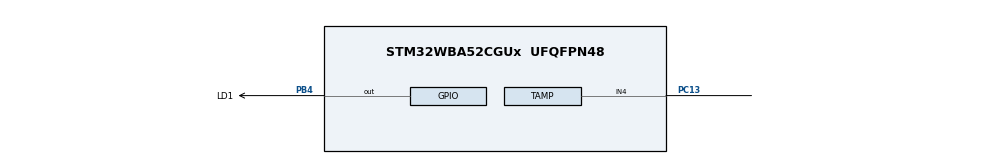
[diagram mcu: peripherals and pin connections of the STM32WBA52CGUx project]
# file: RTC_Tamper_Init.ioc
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CORTEX_M33_NS.userName=CORTEX_M33
Mcu.Family=STM32WBA
Mcu.Name=STM32WBA52CGUx
Mcu.Package=UFQFPN48
NVIC.PriorityGroup=NVIC_PRIORITYGROUP_4
OSC_IN.Mode=HSE-External-Oscillator
OSC_IN.Signal=RCC_OSC_IN
OSC_OUT.Mode=HSE-External-Oscillator
OSC_OUT.Signal=RCC_OSC_OUT
PB4\ (NJTRST).GPIO_Label=LD1
PB4\ (NJTRST).PinState=GPIO_PIN_SET
PB4\ (NJTRST).Signal=GPIO_Output
PC13.Mode=Tamper_4_enabled0
PC13.Signal=TAMP_IN4
ProjectManager.HeapSize=0x200
ProjectManager.StackSize=0x400
ProjectManager.TargetToolchain=EWARM V9.20
RCC.ADCFreq_Value=100000000
RCC.AHB5CLKDivider=DIV4
RCC.AHBFreq_Value=100000000
RCC.APB1Freq_Value=100000000
RCC.APB1TimFreq_Value=100000000
RCC.APB2Freq_Value=100000000
RCC.APB2TimFreq_Value=100000000
RCC.CortexFreq_Value=12500000
RCC.HCLKFreq_Value=100000000
RCC.HSE_VALUE=32000000
RCC.HSI_VALUE=16000000
RCC.LSE_VALUE=32768
RCC.PLLM=4
RCC.PLLN=25
RCC.PLLSourceVirtual=RCC_PLLSOURCE_HSE
RCC.SYSCLKFreq_VALUE=100000000
RCC.SYSCLKSourceVirtual=RCC_SYSCLKSOURCE_PLLCLK
RCC.VCOOutputFreq_Value=200000000
TAMP.Filter=RTC_TAMPERFILTER_8SAMPLE
TAMP.NoErase_4=RTC_TAMPER_ERASE_BACKUP_DISABLE
TAMP.SamplingFrequency=RTC_TAMPERSAMPLINGFREQ_RTCCLK_DIV256
VP_ICACHE_VS_ICACHE.Mode=DirectMappedCache
VP_PWR_VS_SECSignals.Mode=Security/Privilege
VP_RTC_VS_RTC_Activate.Mode=RTC_Enabled
board=custom

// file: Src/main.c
/* USER CODE BEGIN Header */
/**
  ******************************************************************************
  * @file    Examples_LL/RTC/RTC_Tamper_Init/Src/main.c
  * @author  MCD Application Team
  * @brief   This sample code shows how to use STM32WBAxx RTC LL API
  *          to write/read data to/from RTC Backup data registers and demonstrates
  *          the Tamper detection feature.
  ******************************************************************************
  * @attention
  *
  * Copyright (c) 2022 STMicroelectronics.
  * All rights reserved.
  *
  * This software is licensed under terms that can be found in the LICENSE file
  * in the root directory of this software component.
  * If no LICENSE file comes with this software, it is provided AS-IS.
  *
  ******************************************************************************
  */
/* USER CODE END Header */
#include "main.h"

/* USER CODE BEGIN PD */

#define BACKUP_COUNT 32
/* USER CODE END PD */

/* USER CODE BEGIN PV */

__IO FlagStatus TamperStatus = RESET;

/* Backup registers table */
uint32_t aBKPDataReg[BACKUP_COUNT] =
{
  LL_RTC_BKP_DR0,  LL_RTC_BKP_DR1,  LL_RTC_BKP_DR2,
  LL_RTC_BKP_DR3,  LL_RTC_BKP_DR4,  LL_RTC_BKP_DR5,
  LL_RTC_BKP_DR6,  LL_RTC_BKP_DR7,  LL_RTC_BKP_DR8,
  LL_RTC_BKP_DR9,  LL_RTC_BKP_DR10, LL_RTC_BKP_DR11,
  LL_RTC_BKP_DR12, LL_RTC_BKP_DR13, LL_RTC_BKP_DR14,
  LL_RTC_BKP_DR15, LL_RTC_BKP_DR16, LL_RTC_BKP_DR17,
  LL_RTC_BKP_DR18, LL_RTC_BKP_DR19, LL_RTC_BKP_DR20,
  LL_RTC_BKP_DR21, LL_RTC_BKP_DR22, LL_RTC_BKP_DR23,
  LL_RTC_BKP_DR24, LL_RTC_BKP_DR25, LL_RTC_BKP_DR26,
  LL_RTC_BKP_DR27, LL_RTC_BKP_DR28, LL_RTC_BKP_DR29,
  LL_RTC_BKP_DR30, LL_RTC_BKP_DR31
};

/* USER CODE END PV */

void SystemClock_Config(void);
static void MX_GPIO_Init(void);
static void MX_RTC_Init(void);
static void MX_TAMP_RTC_Init(void);
static void MX_ICACHE_Init(void);
/* USER CODE BEGIN PFP */
void     LED_On(void);
void     LED_Blinking(uint32_t Period);
/* USER CODE END PFP */

int main(void)
{
  /* USER CODE BEGIN 1 */

  register uint32_t index = 0;

  /* USER CODE END 1 */

  /* MCU Configuration--------------------------------------------------------*/

  /* Reset of all peripherals, Initializes the Flash interface and the Systick. */

  /* System interrupt init*/
  NVIC_SetPriorityGrouping(NVIC_PRIORITYGROUP_4);

  /* SysTick_IRQn interrupt configuration */
  NVIC_SetPriority(SysTick_IRQn, NVIC_EncodePriority(NVIC_GetPriorityGrouping(),15, 0));

  /* Enable PWR clock interface */

  LL_AHB4_GRP1_EnableClock(LL_AHB4_GRP1_PERIPH_PWR);

  /* USER CODE BEGIN Init */
  /* Enables access to the backup domain */
  LL_PWR_EnableBkUpAccess();

  /* USER CODE END Init */

  /* Configure the system clock */
  SystemClock_Config();

  /* Initialize all configured peripherals */
  MX_GPIO_Init();
  MX_RTC_Init();
  MX_TAMP_RTC_Init();
  MX_ICACHE_Init();
  /* USER CODE BEGIN 2 */
  LL_RTC_ClearFlag_TAMP4(RTC);
  /* Write Data on the Back Up registers  */
  for (index = 0; index < BACKUP_COUNT; index++)
  {
    LL_RTC_BKP_SetRegister(RTC, aBKPDataReg[index], 0xDF59 + (index * 0x5A));
  }

  /* Check Data is stored on the Back Up registers */
  for (index = 0; index < BACKUP_COUNT; index++)
  {
    if (LL_RTC_BKP_GetRegister(RTC, aBKPDataReg[index]) != (0xDF59 + (index * 0x5A)))
    {
      LED_Blinking(LED_BLINK_ERROR);
    }
  }

  /* Wait for Tamper detection */
  while (TamperStatus != SET)
  {
    LL_GPIO_TogglePin(LD1_GPIO_Port, LD1_Pin);
    LL_mDelay(LED_BLINK_FAST);
  }

  /* LD1 On: Tamper button pressed */
  LED_On();

  /* USER CODE END 2 */

  /* Infinite loop */
  while (1)
  {

  }
}

void SystemClock_Config(void)
{
  LL_FLASH_SetLatency(LL_FLASH_LATENCY_3);
  while(LL_FLASH_GetLatency()!= LL_FLASH_LATENCY_3)
  {
  }

  LL_PWR_SetRegulVoltageScaling(LL_PWR_REGU_VOLTAGE_SCALE1);
  LL_RCC_HSE_Enable();

   /* Wait till HSE is ready */
  while(LL_RCC_HSE_IsReady() != 1)
  {
  }

  LL_RCC_LSI1_SetPrescaler(LL_RCC_LSI_DIV_1);
  LL_RCC_LSI1_Enable();

   /* Wait till LSI1 is ready */
  while(LL_RCC_LSI1_IsReady() != 1)
  {
  }

  LL_PWR_EnableBkUpAccess();
  LL_RCC_PLL1_ConfigDomain_SYS(LL_RCC_PLL1SOURCE_HSE, 4, 25, 2);
  LL_RCC_PLL1_EnableDomain_PLL1R();
  LL_RCC_PLL1_SetVCOInputRange(LL_RCC_PLLINPUTRANGE_8_16);
  LL_RCC_PLL1_Enable();

   /* Wait till PLL is ready */
  while(LL_RCC_PLL1_IsReady() != 1)
  {
  }

  LL_RCC_SetSysClkSource(LL_RCC_SYS_CLKSOURCE_PLL1R);

   /* Wait till System clock is ready */
  while(LL_RCC_GetSysClkSource() != LL_RCC_SYS_CLKSOURCE_STATUS_PLL1R)
  {
  }

  LL_RCC_SetAHBPrescaler(LL_RCC_SYSCLK_DIV_1);
  LL_RCC_SetAHB5Prescaler(LL_RCC_AHB5_DIV_4);
  LL_RCC_SetAPB1Prescaler(LL_RCC_APB1_DIV_1);
  LL_RCC_SetAPB2Prescaler(LL_RCC_APB2_DIV_1);
  LL_RCC_SetAPB7Prescaler(LL_RCC_APB7_DIV_1);

  LL_Init1msTick(100000000);

  LL_SetSystemCoreClock(100000000);
}

static void MX_ICACHE_Init(void)
{

  /** Enable instruction cache in 1-way (direct mapped cache)
  */
  LL_ICACHE_SetMode(LL_ICACHE_1WAY);
  LL_ICACHE_Enable();

}

static void MX_RTC_Init(void)
{

  LL_RTC_InitTypeDef RTC_InitStruct = {0};

  if(LL_RCC_GetRTCClockSource() != LL_RCC_RTC_CLKSOURCE_LSI)
  {
    LL_RCC_ForceBackupDomainReset();
    LL_RCC_ReleaseBackupDomainReset();
    LL_RCC_SetRTCClockSource(LL_RCC_RTC_CLKSOURCE_LSI);
  }

  /* Peripheral clock enable */
  LL_APB7_GRP1_EnableClock(LL_APB7_GRP1_PERIPH_RTCAPB);

  /* USER CODE BEGIN RTC_Init 1 */

  /* Enables the PWR Clock and Enables access to the backup domain */
  LL_PWR_EnableBkUpAccess();
  /* USER CODE END RTC_Init 1 */
  RTC_InitStruct.HourFormat = LL_RTC_HOURFORMAT_24HOUR;
  RTC_InitStruct.AsynchPrescaler = 127;
  RTC_InitStruct.SynchPrescaler = 255;
  LL_RTC_Init(RTC, &RTC_InitStruct);
  LL_RTC_SetBackupRegisterPrivilege(RTC, LL_RTC_PRIVILEGE_BKUP_ZONE_NONE);
  LL_RTC_SetBackupRegProtection(RTC, LL_RTC_BKP_DR0, LL_RTC_BKP_DR0);
  LL_RTC_SetRtcPrivilege(RTC, LL_RTC_PRIVILEGE_FULL_NO);
  /* USER CODE BEGIN RTC_Init 2 */
  /* Enable IT TAMPER */
  LL_RTC_EnableIT_TAMP4(RTC);

  /* Configure the NVIC for RTC Tamper */
  NVIC_SetPriority(TAMP_IRQn, 0x0F);
  NVIC_EnableIRQ(TAMP_IRQn);

  /* RTC Tamper Interrupt Configuration: EXTI configuration */
  LL_EXTI_EnableIT_0_31(LL_EXTI_LINE_13);
  LL_EXTI_EnableRisingTrig_0_31(LL_EXTI_LINE_13);

  /* Clear the Tamper interrupt pending bit */
  LL_RTC_ClearFlag_TAMP4(RTC);
  /* USER CODE END RTC_Init 2 */

}

static void MX_TAMP_RTC_Init(void)
{

  /* Peripheral clock enable */

  LL_RTC_SetTampPrivilege(RTC, LL_TAMP_PRIVILEGE_FULL_YES);
  LL_RTC_IncrementMonotonicCounter(RTC);
  LL_RTC_TAMPER_SetFilterCount(RTC, LL_RTC_TAMPER_FILTER_8SAMPLE);
  LL_RTC_TAMPER_SetPrecharge(RTC, LL_RTC_TAMPER_DURATION_1RTCCLK);
  LL_RTC_TAMPER_SetSamplingFreq(RTC, LL_RTC_TAMPER_SAMPLFREQDIV_256);
  LL_RTC_TAMPER_EnablePullUp(RTC);

  /** Enable the RTC Tamper 4
  */
  LL_RTC_TAMPER_Enable(RTC, LL_RTC_TAMPER_4);
  LL_RTC_TAMPER_ATAMP_DisableActiveMode(LL_RTC_TAMPER_ATAMP_TAMP4AM);
  LL_RTC_TAMPER_DisableEraseBKP(RTC, LL_RTC_TAMPER_NOERASE_TAMPER4);
  LL_RTC_TS_EnableOnTamper(RTC);

}

static void MX_GPIO_Init(void)
{
  LL_GPIO_InitTypeDef GPIO_InitStruct = {0};

  /* GPIO Ports Clock Enable */
  LL_AHB2_GRP1_EnableClock(LL_AHB2_GRP1_PERIPH_GPIOC);
  LL_AHB2_GRP1_EnableClock(LL_AHB2_GRP1_PERIPH_GPIOB);

  /**/
  LL_GPIO_SetOutputPin(LD1_GPIO_Port, LD1_Pin);

  /**/
  GPIO_InitStruct.Pin = LD1_Pin;
  GPIO_InitStruct.Mode = LL_GPIO_MODE_OUTPUT;
  GPIO_InitStruct.Speed = LL_GPIO_SPEED_FREQ_LOW;
  GPIO_InitStruct.OutputType = LL_GPIO_OUTPUT_PUSHPULL;
  GPIO_InitStruct.Pull = LL_GPIO_PULL_NO;
  LL_GPIO_Init(LD1_GPIO_Port, &GPIO_InitStruct);

}

/* USER CODE BEGIN 4 */

/**
  * @brief  Turn-on LD1.
  * @param  None
  * @retval None
  */
void LED_On(void)
{
  /* Turn LD1 on */
  LL_GPIO_ResetOutputPin(LD1_GPIO_Port, LD1_Pin);
}

/**
  * @brief  Set LD1 to Blinking mode for an infinite loop (toggle period based on value provided as input parameter).
  * @param  Period : Period of time (in ms) between each toggling of LED
  *   This parameter can be user defined values. Pre-defined values used in that example are :
  *     @arg LED_BLINK_FAST : Fast Blinking
  *     @arg LED_BLINK_SLOW : Slow Blinking
  *     @arg LED_BLINK_ERROR : Error specific Blinking
  * @retval None
  */
void LED_Blinking(uint32_t Period)
{
  /* Toggle IO in an infinite loop */
  while (1)
  {
    LL_GPIO_TogglePin(LD1_GPIO_Port, LD1_Pin);
    LL_mDelay(Period);
  }
}

/******************************************************************************/
/*   USER IRQ HANDLER TREATMENT                                               */
/******************************************************************************/
/**
  * @brief  Tamper event callback function
  * @param  None
  * @retval None
  */
void Tamper_Callback(void)
{
  register uint32_t index = 0;

  /* Deactivate the tamper */
  LL_RTC_TAMPER_Disable(RTC, LL_RTC_TAMPER_4);

  /* Check Data is cleared on the Back Up registers */
  for (index = 0; index < BACKUP_COUNT; index++)
  {
    if (LL_RTC_BKP_GetRegister(RTC, aBKPDataReg[index]) != 0x00)
    {
      LED_Blinking(LED_BLINK_ERROR);
    }
  }
  TamperStatus = SET;
}

/* USER CODE END 4 */

void Error_Handler(void)
{
}
